# MM32F013x register map
File version: 1.01
CPU: CM0 r0p0, little endian, no MPU, no FPU, 2 interrupt priority bits
Registers are 32-bit, read-write, reset 0x0 unless marked. A register's access mark holds for its fields unless they carry their own. Offsets are from the block's base; [hi:lo] are bit positions; {n}, {i} and the like mark numbered series.

## BKP — Backup registers
Base 0x40002840
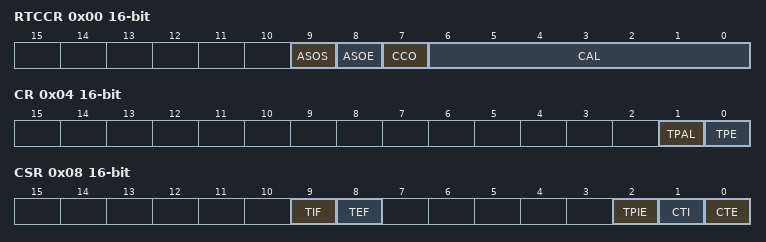
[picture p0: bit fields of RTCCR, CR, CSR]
0x00 RTCCR 16-bit — RTC clock calibration register
  [9] ASOS — Alarm or second output selection
  [8] ASOE — Alarm or second output enable
  [7] CCO — Calibration clock output
  [6:0] CAL — Calibration value
0x04 CR 16-bit — Backup control register
  [1] TPAL — TAMPER pin active level
  [0] TPE — TAMPER pin enable
0x08 CSR 16-bit — BKP control/status register
  [9] TIF — Tamper interrupt flag
  [8] TEF — Tamper event flag
  [2] TPIE — TAMPER pin interrupt enable
  [1] CTI — Clear tamper interrupt
  [0] CTE — Clear tamper event
{0xC+4i} DR{i} (i=1..20) — Backup data register(BKP_DR)
  [15:0] D — Backup data

## COMP — Comparator
Base 0x40013C00
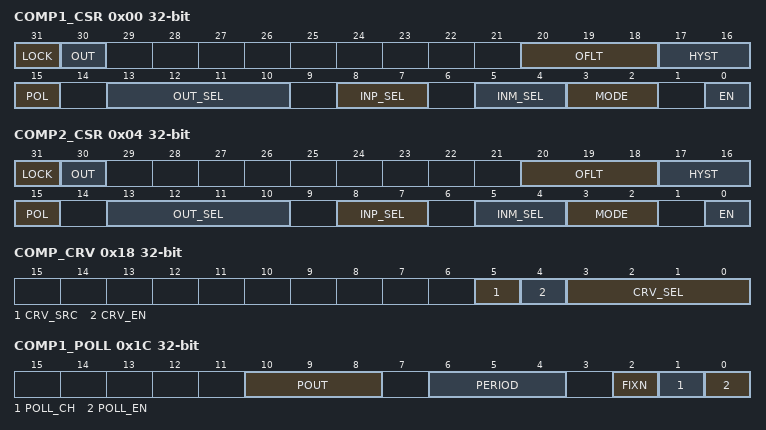
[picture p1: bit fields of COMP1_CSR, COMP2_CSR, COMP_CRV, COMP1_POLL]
0x00 COMP1_CSR — COMP1 Control State Register
  [31] LOCK — Comparator lock
  [30] OUT — Comparator 1 lock
  [20:18] OFLT — Comparator output filter
  [17:16] HYST — Comparator 1 hysteresis
  [15] POL — Comparator 1 output polarity
  [13:10] OUT_SEL — Comparator 1 output selection
  [8:7] INP_SEL — Comparator 1 normal phase input selection
  [5:4] INM_SEL — Comparator 1 inverting input selection
  [3:2] MODE — Comparator 1 mode
  [0] EN — Comparator 1 enable
0x04 COMP2_CSR — COMP2 Control State Register
  [31] LOCK — Comparator lock
  [30] OUT — Comparator 2 lock
  [20:18] OFLT — Comparator output filter
  [17:16] HYST — Comparator 2 hysteresis
  [15] POL — Comparator 2 output polarity
  [13:10] OUT_SEL — Comparator 2 output selection
  [8:7] INP_SEL — Comparator 2 normal phase input selection
  [5:4] INM_SEL — Comparator 2 inverting input selection
  [3:2] MODE — Comparator 2 mode
  [0] EN — Comparator 2 enable
0x18 COMP_CRV — COMP Extern Reference Voltage
  [5] CRV_SRC — Comparator external reference voltage source select
  [4] CRV_EN — Comparator external reference voltage enable
  [3:0] CRV_SEL — Comparator external reference voltage select
0x1C COMP1_POLL — COMP1 Polling Output Register
  [10:8] POUT — Comparator 1 Polling output
  [6:4] PERIOD — Comparator 1 polling wait cycle
  [2] FIXN — Comparator 1 Polling inverting input fix
  [1] POLL_CH — Comparator 1 polling pollingchannel
  [0] POLL_EN — Comparator 1 polling enable
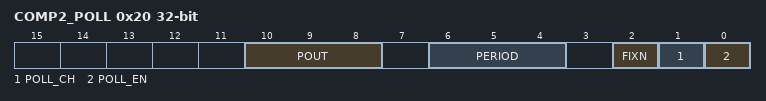
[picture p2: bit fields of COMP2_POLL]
0x20 COMP2_POLL — COMP2 Polling Output Register
  [10:8] POUT — Comparator 2 Polling output
  [6:4] PERIOD — Comparator 2 polling wait cycle
  [2] FIXN — Comparator 2 Polling inverting input fix
  [1] POLL_CH — Comparator 2 polling channel
  [0] POLL_EN — Comparator 2 polling enable

## CRC — CRC calculation unit
Base 0x40023000
0x00 DR reset 0xFFFFFFFF — Data register
  [31:0] DR — Data register bits
0x04 IDR — Independent data register
  [7:0] IDR — General-purpose 8-bit data register bits
0x08 CTRL wo — Control register
  [0] RESET — CRC reset
0x20 REVERSE — Reversed data register
  [0] REVERSE — Data reverse register bits

## CSM — Debug support
Base 0x40006800
0x00 TXREG1 — Transmit register 1
  [31:0] TXREG1 — Transfer data
0x04 TXREG2 — Transmit register 2
  [31:0] TXREG2 — Transfer data
0x08 RXREG1 ro — Reveive register 1
  [31:0] RXREG1 — Receive data
0x0C RXREG2 ro — Reveive register 2
  [31:0] RXREG2 — Receive data
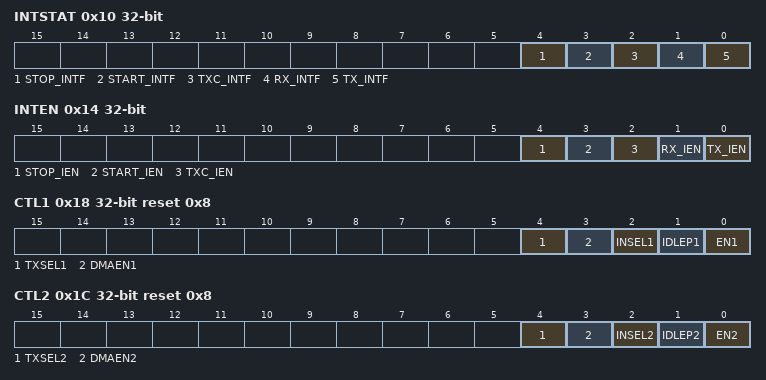
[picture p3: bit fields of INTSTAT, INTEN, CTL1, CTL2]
0x10 INTSTAT — Interrupt Status Register
  [4] STOP_INTF — Stop Reveive data interrupt flag
  [3] START_INTF — Start Reveive data interrupt flag
  [2] TXC_INTF — Transmit complete interrupt flag
  [1] RX_INTF — Receive data available interrupt flag
  [0] TX_INTF — Transmit FIFO available interrupt flag
0x14 INTEN — Interrupt Enable Register
  [4] STOP_IEN — Stop Reveive data interrupt enable
  [3] START_IEN — Start Reveive data interrupt enable
  [2] TXC_IEN — Transmit complete interrupt enable
  [1] RX_IEN — Receive data available interrupt enable
  [0] TX_IEN — Transmit FIFO available interrupt enable
0x18 CTL1 reset 0x8 — Control Register 1
  [4] TXSEL1 — TXandRX data select control
  [3] DMAEN1 — DMA enable bit
  [2] INSEL1 — input signal select
  [1] IDLEP1 — idel state polority
  [0] EN1 — enable Control bit
0x1C CTL2 reset 0x8 — Control Register 2
  [4] TXSEL2 — TXandRX data select control
  [3] DMAEN2 — DMA enable bit
  [2] INSEL2 — input signal select
  [1] IDLEP2 — idel state polority
  [0] EN2 — enable Control bit
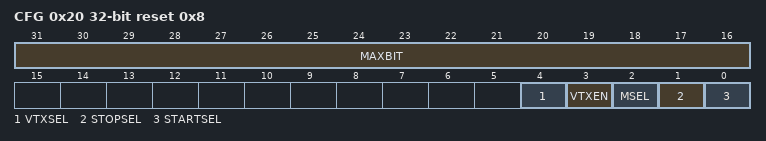
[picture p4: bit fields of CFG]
0x20 CFG reset 0x8 — Configure Register
  [31:16] MAXBIT — max tx and rx bit
  [4] VTXSEL — Vtx select
  [3] VTXEN — Vtx enable
  [2] MSEL — master or slave select
  [1] STOPSEL — stop select
  [0] STARTSEL — start select
0x24 SPBRG reset 0x2 — Baud rate register
  [15:0] SPBRG — baud rate control register for simple data
0x28 BCNT — bit count
  [15:0] CNT — send or receive bit count
